# MCU_PLL0_CFG register map
Vendor: Texas Instruments
Peripheral module from a debugger description file (folder J7VCL).
Registers are 32-bit, access per field, reset 0x0 unless marked. A register's access mark holds for its fields unless they carry their own. Offsets are as the file gives them; lines under a group give offsets from that group; [hi:lo] are bit positions; {n}, {i} and the like mark numbered series; 'fields as' and 'values as' point back to an identical list; <NAME> marks a mode.

## MCU_PLL0_CFG
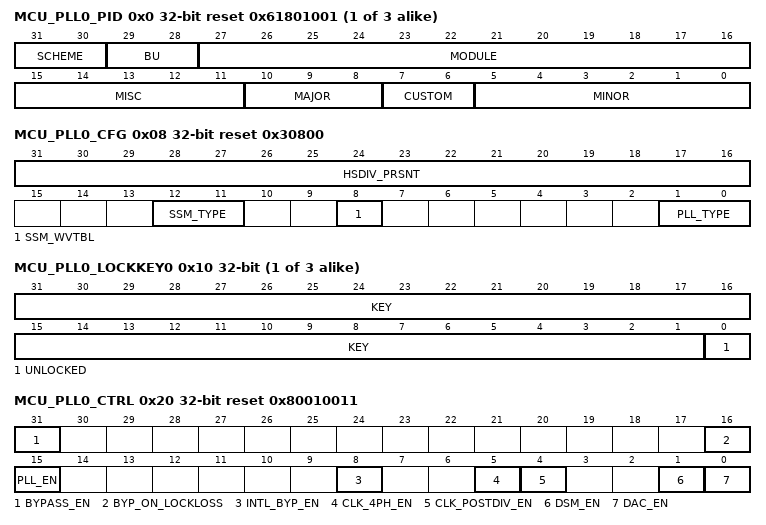
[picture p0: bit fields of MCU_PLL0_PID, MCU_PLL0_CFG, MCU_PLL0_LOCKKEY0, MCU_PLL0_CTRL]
{0x0+0x1000*i} MCU_PLL{i}_PID ro reset 0x61801001 (i=0..2) — Return to the . Peripheral Identification Register
  [31:30] SCHEME — Peripheral Identification Register Scheme
  [29:28] BU — Business Unit - Processors
  [27:16] MODULE — Module functional identifier
  [15:11] MISC — Misc revision number
  [10:8] MAJOR — Major revision number
  [7:6] CUSTOM — custom revision number
  [5:0] MINOR — Minor revision number
0x08 MCU_PLL0_CFG ro reset 0x30800 — Return to the . PLL MMR Configuration
  [31:16] HSDIV_PRSNT — High Speed Divider Presence Each bit Indicates the presence of High Speed dividers 0-15.By definition HSDIV[4:0] are connected the PLL FOUTVCO output clock and HSDIV[15:5] are connected to the PLL FOUTPOSTDIV output clock
  [12:11] SSM_TYPE — Spread spectrum module presence Field values (Others are reserved):2'b00 - SSM is not present 2'b01 - SSM is present 2'b10 - Reserved 2'b11 - Reserved
  [8] SSM_WVTBL — Spread spectrum wave table presence1'b0 - SSM Wave table is not present 1'b1 - SSM Wave table is present
  [1:0] PLL_TYPE — Indicates PLL type Field values (Others are reserved):2'b00 - Fractional PLL 2'b01 - FractionalF PLL 2'b10 - De-Skew PLL
{0x10+0x1000*i} MCU_PLL{i}_LOCKKEY0 (i=0..2) — Return to the . PLL{i} Lock Key 0 Register
  [31:1] KEY rw — Write the kick0 unlock value followed by the kick1 unlock value to unlock the write-protected Partition{i} registers
  [0] UNLOCKED ro — Unlock status.When set, indicates that the proper unlock sequence has been performed and the partition is unlocked for writing.
{0x14+0x1000*i} MCU_PLL{i}_LOCKKEY1 rw (i=0..2) — Return to the . PLL{i} Lock Key 1 RegisterAddr
  [31:0] LOCKKEY1_VAL — Write the kick1 unlock value after the kick0 unlock value to unlock the write-protected Partition{i} registers
0x20 MCU_PLL0_CTRL reset 0x80010011 — Return to the . PLL0 Control
  [31] BYPASS_EN rw — Bypass enable.This controls the glitch-free bypass mux. The bypass_en bit should be set prior tomaking any changes to the PLL settings. 1'b0 - Synchronously select PLL and associated HSDIV clock outputs 1'b1 - Synchronously select the reference clock for all PLL and HSDIV clock outputs
  [16] BYP_ON_LOCKLOSS rw — Bypass on loss of PLL lock.This bit controls the PLL bypass mux to automatically switch the clock source to the reference clock when the PLL losses lock. 1'b0 - Do not automatically switch to ref clock source on PLL lock loss 1'b1 - Switch to ref clock source when PLL losses lock
  [15] PLL_EN rw — PLL enable1'b0 - PLL is disabled 1'b1 - PLL is enabled
  [8] INTL_BYP_EN rw — PLL internal bypass enable.This is an asynchronous mux which can produce glitches on the output clocks during switching. 1'b0 - Output clocks are derived from the VCO clock 1'b1 - Output clocks are derived from the FREF reference clock
  [5] CLK_4PH_EN rw — Enable 4-phase clock generator.This bit is ignored if clk_postdiv_en=0 1'b0 - 4-phase dividers disabled. FOUT1PHx and FOUTn clocks are held low. 1'b1 - 4-phase dividers enabled. FOUT1PH0/90/180/270 and FOUT2, FOUT3, FOUT4 clocks are enabled.
  [4] CLK_POSTDIV_EN rw — Post divide CLK enable1'b0 - Post divide powered down. FOUTPOSTDIV and all auxiliary PLL clocks (4-phase and synchronous divided clocks) are held low 1'b1 - Post divide enabled. FOUTPOSTDIV, 4-phase and synchronous clocks are enabled.
  [1] DSM_EN rw — Delta-Sigma modulator enable1'b0 - Delta-Sigma modulator is disabled (use integer divide mode) 1'b1 - Delta-Sigma modulator is enabled (use fractional divide mode)
  [0] DAC_EN rw — Enable fractional noise canceling DAC This bit has no function (DAC is always disabled) in integer divide mode (when dsm_en=0)1'b0 - Fractional NC DAC is disabled (for Test modes only) 1'b1 - Fractional NC DAC is enabled (ignored in integer divide mode)
{0x24+0x1000*i} MCU_PLL{i}_STAT ro (i=0..2) — Return to the . PLL{i} Status
  [0] LOCK — PLL lock status.Software should wait for lock to be asserted before clearing the PLL_CTRL_bypass_en bit 1'b0 - PLL is not locked 1'b1 - PLL is locked
0x30 MCU_PLL0_FREQ_CTRL0 reset 0x10 — Return to the . PLL0 Frequency Control 0 Register
  [11:0] FB_DIV_INT rw — PLL feedback divider (integer portion) In Integer mode values of 16 - 3200 (dec) are supported.In Fractional mode values of 20 to 320 are supported. 12'h010 - Divide by 16 12'h011 - Divide by 17 : 12'h140 - Divide by 320 : 12'hC80 - Divide by 3200 12'hC81 - 12'hFFF - Not supported
{0x34+0x1000*i} MCU_PLL{i}_FREQ_CTRL1 (i=0..2) — Return to the . PLL0 Frequency Control 1 Register
  [23:0] FB_DIV_FRAC rw — PLL feedback divider (fractional portion) Supports values of 0 to 0.999999940395.The total feedback divide value is (fb_div_int + fb_div_frac / (2)) 24'h000000 - 0 24'h000001 - .000000059605 (1/(2)) 24'h000002 - .000000119209 (2/(2)) : 24'h800000 - .500000000000 : 24'hFFFFFF - .999999940395 (1677215/(2))
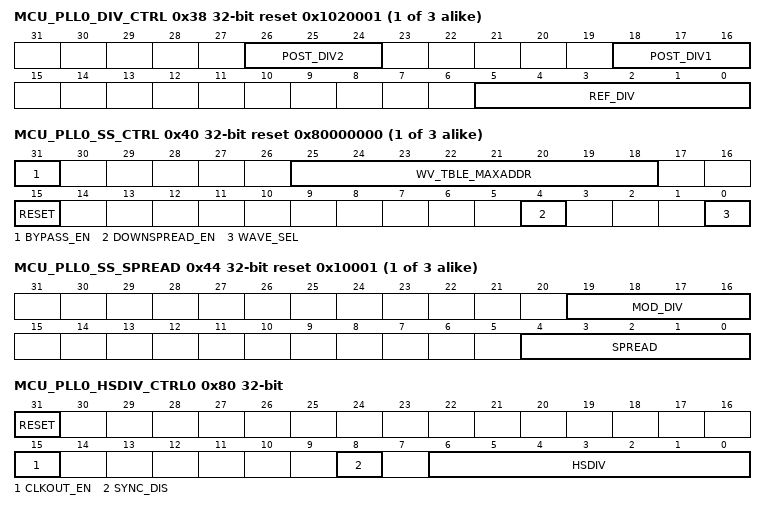
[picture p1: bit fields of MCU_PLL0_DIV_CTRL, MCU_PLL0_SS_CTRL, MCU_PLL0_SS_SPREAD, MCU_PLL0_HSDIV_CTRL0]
{0x38+0x1000*i} MCU_PLL{i}_DIV_CTRL reset 0x1020001 (i=0..2) — Return to the . PLL{i} Output Clock Divider Register
  [26:24] POST_DIV2 rw — Secondary post divider.Supports values of 1-7
  [18:16] POST_DIV1 rw — Primary post divider.To ensure correct operation, post_div1 must always be programmed to a value equal to or greater that post_div2. Supports values of 1-7i Field values (Others are reserved): 3'b000 - Reserved (do not use) 3'b001 - Divide by 1 3'b010 - Divide by 2 3'b011 - Divide by 3 3'b100 - Divide by 4 3'b101 - Divide by 5 3'b110 - Divide by 6 3'b111 - Divide by 7
  [5:0] REF_DIV rw — Reference clock pre-divider.Supports values of 1-63 6'b000000 - Reserved /(do not use/) 6'b000001 - Divide by 1 6'b000010 - Divide by 2 : 6'b111111 - Divide by 63
{0x40+0x1000*i} MCU_PLL{i}_SS_CTRL reset 0x80000000 (i=0..2) — Return to the . PLL_SS_CTRL register for PLL{i}
  [31] BYPASS_EN rw — Bypass the SS modulator.1'b0 - Spread spectrum modulation is enabled 1'b1 - SSMOD is bypassed. No modulation of PLL frequency
  [25:18] WV_TBLE_MAXADDR rw — Wave table max address.Indicates the maximum number of address bits used to access the external wave table. These bits are not used if PLL_CFG_ssm_wvtbl = 0
  [15] RESET rw — SSM reset.When set to 1 the SSM modulator is in reset
  [4] DOWNSPREAD_EN rw — Selects center spread or down spread clock variance 1'b0 - Center spread 1'b1 - Down spread
  [0] WAVE_SEL rw — Wave pattern select External wave table should only be selected if PLL_CFG_ssm_wvtbl = 1 Field values (Others are reserved):1'b0 - Use 128 point triangle wave table 1'b1 - Use external wave table
{0x44+0x1000*i} MCU_PLL{i}_SS_SPREAD reset 0x10001 (i=0..2) — Return to the . PLL_SS_SPREAD register for PLL{i}
  [19:16] MOD_DIV rw — Input clock divider.This divider sets the modulation frequency. Supports divide values of 1-63
  [4:0] SPREAD rw — Sets the spread modulation depth.The depth is spread*0.1% 5'b00000 - Reserved (don't use) 5'b00001 - 0.1% 5'b00010 - 0.2% : 5'b10000 - 1.6% : 5'b11111 - 3.1%
0x80 MCU_PLL0_HSDIV_CTRL0 — Return to the . HSDIV_CTRL0 register for PLL0
  [31] RESET rw — SSM reset.When set to 1 the SSM modulator is in resetl
  [15] CLKOUT_EN rw — CLKOUT1 enable1'b0 - Synchronously disable CLKOUT1 1'b1 - Synchronously enable CLKOUT1
  [8] SYNC_DIS rw — Disable divider synchronization logic0 - Changes to DIV value synchronized to prevent glitches 1 - Changes are asynchronous
  [6:0] HSDIV rw — CLKOUT0 divider value (HSDIV1+1) Allowed values are 0-127
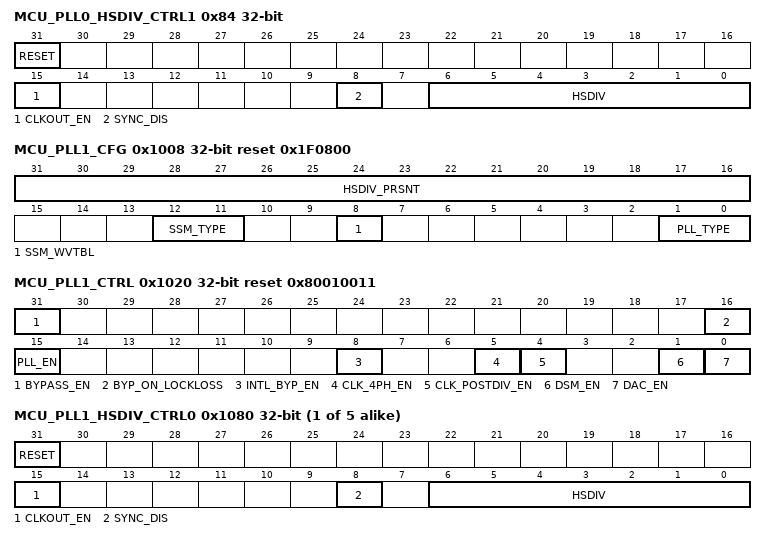
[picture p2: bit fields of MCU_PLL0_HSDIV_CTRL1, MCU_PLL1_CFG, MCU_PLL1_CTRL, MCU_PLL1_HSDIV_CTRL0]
0x84 MCU_PLL0_HSDIV_CTRL1 — Return to the . HSDIV_CTRL1 register for PLL0
  fields as MCU_PLL0_HSDIV_CTRL0
0x1008 MCU_PLL1_CFG ro reset 0x1F0800 — Return to the . PLL MMR Configuration
  fields as MCU_PLL0_CFG
0x1020 MCU_PLL1_CTRL reset 0x80010011 — Return to the . PLL1 Control
  [31] BYPASS_EN rw — Bypass enable.This controls the glitch-free bypass mux. The bypass_en bit should be set prior tomaking any changes to the PLL settings. 1'b0 - Synchronously select PLL and associated HSDIV clock outputs 1'b1 - Synchronously select the reference clock for all PLL and HSDIV clock outputs
  [16] BYP_ON_LOCKLOSS rw — Bypass on loss of PLL lock.This bit controls the PLL bypass mux to automatically switch the clock source to the reference clock when the PLL losses lock. 1'b0 - Do not automatically switch to ref clock source on PLL lock loss 1'b1 - Switch to ref clock source when PLL losses lock
  [15] PLL_EN rw — PLL enable1'b0 - PLL is disabled 1'b1 - PLL is enabled
  [8] INTL_BYP_EN rw — PLL internal bypass enable.This is an asynchronous mux which can produce glitches on the outputclocks during switching. 1'b0 - Output clocks are derived from the VCO clock 1'b1 - Output clocks are derived from the FREF reference clock
  [5] CLK_4PH_EN rw — Enable 4-phase clock generator.This bit is ignored if clk_postdiv_en=0 1'b0 - 4-phase dividers disabled. FOUT1PHx and FOUTn clocks are held low. 1'b1 - 4-phase dividers enabled. FOUT1PH0/90/180/270 and FOUT2, FOUT3, FOUT4 clocks are enabled.
  [4] CLK_POSTDIV_EN rw — Post divide CLK enable1'b0 - Post divide powered down. FOUTPOSTDIV and all auxiliary PLL clocks (4-phase and synchronous divided clocks) are held low 1'b1 - Post divide enabled. FOUTPOSTDIV, 4-phase and synchronous clocks are enabled.
  [1] DSM_EN rw — Delta-Sigma modulator enable1'b0 - Delta-Sigma modulator is disabled (use integer divide mode) 1'b1 - Delta-Sigma modulator is enabled (use fractional divide mode)
  [0] DAC_EN rw — Enable fractional noise canceling DAC This bit has no function (DAC is always disabled) in integer divide mode (when dsm_en=0)1'b0 - Fractional NC DAC is disabled (for Test modes only) 1'b1 - Fractional NC DAC is enabled (ignored in integer divide mode)
0x1030 MCU_PLL1_FREQ_CTRL0 reset 0x10 — Return to the . PLL1 Frequency Control 1 Register
  [11:0] FB_DIV_INT rw — PLL feedback divider (integer portion) In Integer mode values of16 - 3200 (dec) are supported. In Fractional mode values of 20 to 320 are supported. 12'h010 - Divide by 16 12'h011 - Divide by 17 : 12'h140 - Divide by 320 : 12'hC80 - Divide by 3200 12'hC81 - 12'hFFF - Not supported
{0x1080+4i} MCU_PLL1_HSDIV_CTRL{i} (i=0..4) — Return to the . HSDIV_CTRL{i} register for PLL1
  fields as MCU_PLL0_HSDIV_CTRL0
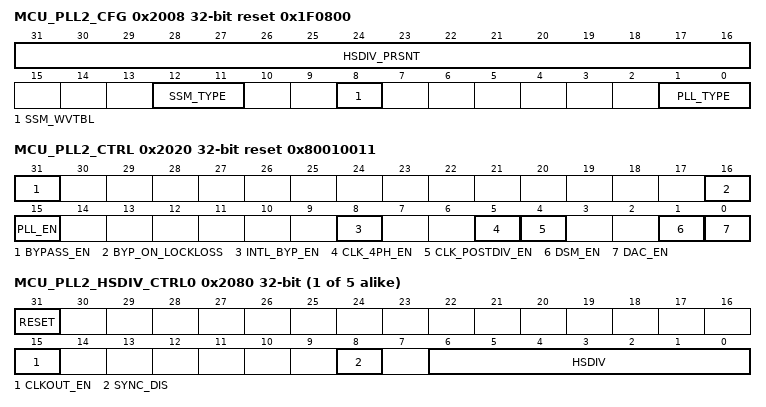
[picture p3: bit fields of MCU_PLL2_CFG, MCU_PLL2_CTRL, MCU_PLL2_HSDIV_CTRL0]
0x2008 MCU_PLL2_CFG ro reset 0x1F0800 — Return to the . PLL MMR Configuration
  fields as MCU_PLL0_CFG
0x2020 MCU_PLL2_CTRL reset 0x80010011 — Return to the . PLL2 Control
  fields as MCU_PLL1_CTRL
0x2030 MCU_PLL2_FREQ_CTRL0 reset 0x10 — Return to the . PLL2 Frequency Control 2 Register
  fields as MCU_PLL1_FREQ_CTRL0
{0x2080+4i} MCU_PLL2_HSDIV_CTRL{i} (i=0..4) — Return to the . HSDIV_CTRL{i} register for PLL2
  fields as MCU_PLL0_HSDIV_CTRL0
